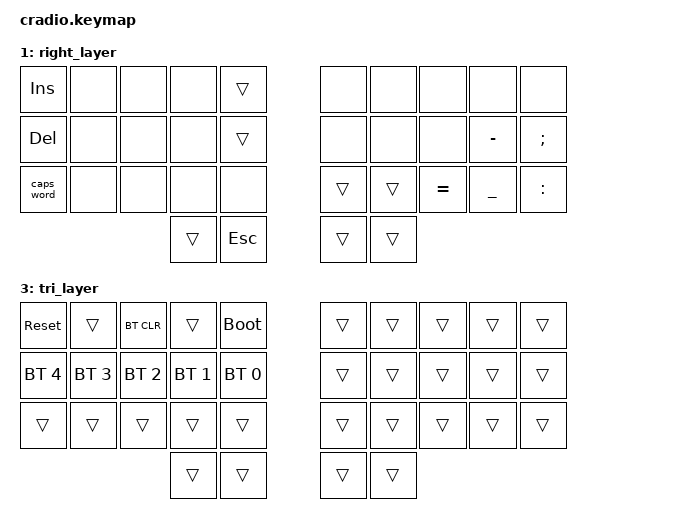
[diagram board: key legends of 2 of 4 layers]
// Copyright (c) 2022 The ZMK Contributors
// SPDX-License-Identifier: MIT

#include <behaviors.dtsi>
#include <dt-bindings/zmk/keys.h>
#include <dt-bindings/zmk/bt.h>

// Home row mods macro
#define LHRM(k1,k2,k3,k4) &ht LGUI k1  &ht LALT k2  &ht LCTRL k3  &ht LSHFT k4
#define RHRM(k1,k2,k3,k4) &ht RSHFT k1  &ht RCTRL k2  &ht RALT k3  &ht RGUI k4

/ {
    behaviors {
        ht: hold_tap {
            compatible = "zmk,behavior-hold-tap";
            #binding-cells = <2>;
            flavor = "tap-preferred";
            tapping-term-ms = <220>;
            quick-tap-ms = <150>;
            require-prior-idle-ms = <100>;
            bindings = <&kp>, <&kp>;
        };
    };

    conditional_layers {
        compatible = "zmk,conditional-layers";
        tri_layer {
            if-layers = <1 2>;
            then-layer = <3>;
        };
    };

    keymap {
        compatible = "zmk,keymap";
        //╭──────────┬──────────┬──────────┬──────────┬──────────╮   ╭──────────┬──────────┬──────────┬──────────┬──────────╮
        //│  Q       │  W       │  E       │  R       │  T       │   │  Y       │  U       │  I       │  O       │  P       │
        //├──────────┼──────────┼──────────┼──────────┼──────────┤   ├──────────┼──────────┼──────────┼──────────┼──────────┤
        //│  A       │  S       │  D       │  F       │  G       │   │  H       │  J       │  K       │  L       │ ' "      │
        //├──────────┼──────────┼──────────┼──────────┼──────────┤   ├──────────┼──────────┼──────────┼──────────┼──────────┤
        //│  Z       │  X       │  C       │  V       │  B       │   │  N       │  M       │ , <      │ . >      │ / ?      
        //╰──────────┴──────────┴──────────┼──────────┼──────────┤   ├──────────┼──────────┼──────────┴──────────┴──────────╯
        //                                 ╰──────────┴──────────╯   ╰──────────┴──────────╯
        default_layer { 
        bindings = <
            &kp Q      &kp W      &kp E      &kp R      &kp T          &kp Y      &kp U      &kp I      &kp O      &kp P
            LHRM(A,        S,         D,         F)     &kp G          &kp H      RHRM(J,        K,         L,        SQT)
            &ht LCTRL Z &kp X      &kp C      &kp V      &kp B          &kp N      &kp M      &kp COMMA  &kp DOT    &kp FSLH
                                            &lt 2 TAB   &kp ENTER     &kp SPACE  &lt 1 TAB
            >;
        };

        right_layer {
            bindings = <

            &kp INS    &none     &none     &none     &trans         &none   &none  &none  &none    &none
            &kp DEL    &none     &none     &none     &trans         &none   &none  &none  &kp MINUS    &kp SEMI
           &caps_word  &none     &none     &none     &none          &trans  &trans &kp EQUAL &kp UNDER &kp COLON
                                             &trans     &kp ESC        &trans     &trans
            >;
        };

        left_layer {
            bindings = <
        //╭──────────┬──────────┬──────────┬──────────┬──────────╮   ╭──────────┬──────────┬──────────┬──────────┬──────────╮
        //│          │  [       │  {       │  }       │          │   │  7 &     │  8 *     │  9 (     │         │         │
        //├──────────┼──────────┼──────────┼──────────┼──────────┤   ├──────────┼──────────┼──────────┼──────────┼──────────┤
        //│  !       │  @       │  #       │  $       │  %       │   │  4 %     │  5 %     │  6 ^     │         │  `       │
        //├──────────┼──────────┼──────────┼──────────┼──────────┤   ├──────────┼──────────┼──────────┼──────────┼──────────┤
        //│          │          │          │          │          │   │  1 !     │  2 @     │  3 #     │         │          │
        //╰──────────┴──────────┴──────────┼──────────┼──────────┤   ├──────────┼──────────┼──────────┴──────────┴──────────╯
        //                                 ╰──────────┴──────────╯   ╰──────────┴──────────╯
//            &trans     &kp LBKT   &kp LBRC   &kp RBRC   &trans         &kp CARET  &kp LPAR   &kp RPAR   &kp RBKT   &kp TILDE
//            &kp EXCL   &kp AT     &kp HASH   &kp DLLR   &kp PRCNT      &kp ASTRK  &kp MINUS  &kp EQUAL  &kp BSLH   &kp GRAVE
//            &trans     &trans     &trans     &trans     &trans         &kp AMPS   &kp UNDER  &kp PLUS   &kp PIPE   &trans
//                                             &trans     &trans         &trans     &trans


            &kp HOME   &kp PG_DN  &kp PG_UP  &kp END    &kp (0x35)    &kp MINUS    &kp NUMBER_7      &kp NUMBER_8    &kp NUMBER_9   &kp EQUAL     // &kp (0x2F) [  &kp (0x30) ]  -=_+ []{}
            LHRM(LEFT,     DOWN,      UP,        RIGHT) &none         RHRM(LBKT,       NUMBER_4,         NUMBER_5,       NUMBER_6)  &kp RBKT     // &kp (0x33)
            &trans     &trans     &kp BSPC   &kp DELETE &none         &kp BSLH     &kp NUMBER_1       &kp NUMBER_2   &kp NUMBER_3   &kp (0x38)
                                             &trans     &trans        &kp NUMBER_0 &trans        

            >;
        };

        tri_layer {
            bindings = <
        //╭──────────┬──────────┬──────────┬──────────┬──────────╮   ╭──────────┬──────────┬──────────┬──────────┬──────────╮
        //│   RESET  │          │ CLEAR BT │          │BOOTLOADER│   │          │          │          │          │          │
        //├──────────┼──────────┼──────────┼──────────┼──────────┤   ├──────────┼──────────┼──────────┼──────────┼──────────┤
        //│PROFILE 4 │PROFILE 3 │PROFILE 2 │PROFILE 1 │PROFILE 0 │   │          │          │          │          │          │
        //├──────────┼──────────┼──────────┼──────────┼──────────┤   ├──────────┼──────────┼──────────┼──────────┼──────────┤
        //│          │          │          │          │          │   │          │          │          │          │          │
        //╰──────────┴──────────┴──────────┼──────────┼──────────┤   ├──────────┼──────────┼──────────┴──────────┴──────────╯
        //                                 ╰──────────┴──────────╯   ╰──────────┴──────────╯
    &sys_reset    &trans       &bt BT_CLR  &trans       &bootloader    &trans     &trans     &trans     &trans      &trans    
    &bt BT_SEL 4 &bt BT_SEL 3 &bt BT_SEL 2 &bt BT_SEL 1 &bt BT_SEL 0   &trans     &trans     &trans     &trans     &trans    
    &trans       &trans       &trans       &trans       &trans         &trans     &trans     &trans     &trans     &trans
                                           &trans       &trans         &trans     &trans
            >;
        };
    };
};
